# CC1312PSIP register map
File version: 1.0
CPU: CM4 1.0, other endian, MPU, FPU, 3 interrupt priority bits
Registers are 32-bit, read-write, reset 0x0 unless marked. A register's access mark holds for its fields unless they carry their own. Offsets are from the block's base; [hi:lo] are bit positions; {n}, {i} and the like mark numbered series; 'fields as' and 'values as' point back to an identical list.

## CPU_DWT — Cortex-M's Data watchpoint and Trace (DWT)
Base 0xE0001000
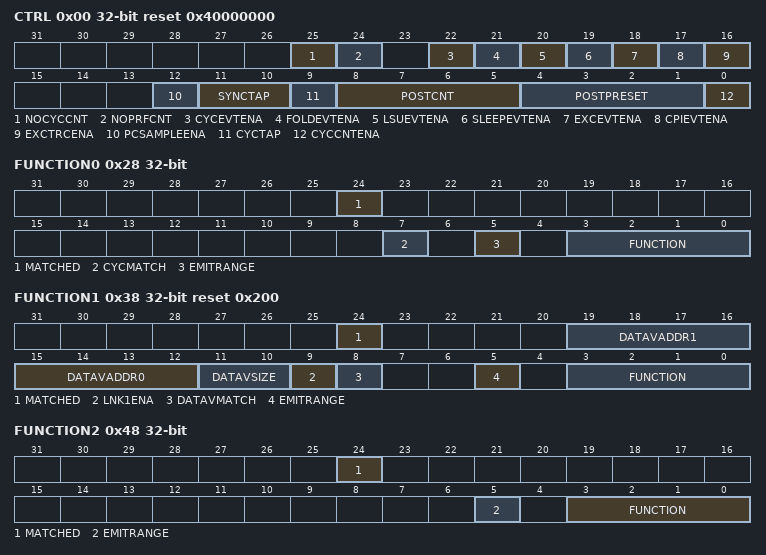
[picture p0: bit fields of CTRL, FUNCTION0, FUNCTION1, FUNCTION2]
0x00 CTRL reset 0x40000000 — Control Use the DWT Control Register to enable the DWT unit.
  [25] NOCYCCNT — [25:25] When set, CYCCNT is not supported.
  [24] NOPRFCNT — [24:24] When set, FOLDCNT, LSUCNT, SLEEPCNT, EXCCNT, and CPICNT are not supported.
  [22] CYCEVTENA — [22:22] Enables Cycle count event. Emits an event when the POSTCNT counter triggers it. See CYCTAP and POSTPRESET for details. This event is only emitted if PCSAMPLEENA is disabled. PCSAMPLEENA overrides the setting of this bit. 0: Cycle count events disabled 1: Cycle count events enabled
  [21] FOLDEVTENA — [21:21] Enables Folded instruction count event. Emits an event when FOLDCNT overflows (every 256 cycles of folded instructions). A folded instruction is one that does not incur even one cycle to execute. For example, an IT instruction is folded away and so does not use up one cycle. 0: Folded instruction count events disabled. 1: Folded instruction count events enabled.
  [20] LSUEVTENA — [20:20] Enables LSU count event. Emits an event when LSUCNT overflows (every 256 cycles of LSU operation). LSU counts include all LSU costs after the initial cycle for the instruction. 0: LSU count events disabled. 1: LSU count events enabled.
  [19] SLEEPEVTENA — [19:19] Enables Sleep count event. Emits an event when SLEEPCNT overflows (every 256 cycles that the processor is sleeping). 0: Sleep count events disabled. 1: Sleep count events enabled.
  [18] EXCEVTENA — [18:18] Enables Interrupt overhead event. Emits an event when EXCCNT overflows (every 256 cycles of interrupt overhead). 0x0: Interrupt overhead event disabled. 0x1: Interrupt overhead event enabled.
  [17] CPIEVTENA — [17:17] Enables CPI count event. Emits an event when CPICNT overflows (every 256 cycles of multi-cycle instructions). 0: CPI counter events disabled. 1: CPI counter events enabled.
  [16] EXCTRCENA — [16:16] Enables Interrupt event tracing. 0: Interrupt event trace disabled. 1: Interrupt event trace enabled.
  [12] PCSAMPLEENA — [12:12] Enables PC Sampling event. A PC sample event is emitted when the POSTCNT counter triggers it. See CYCTAP and POSTPRESET for details. Enabling this bit overrides CYCEVTENA. 0: PC Sampling event disabled. 1: Sampling event enabled.
  [11:10] SYNCTAP — [11:10] Selects a synchronization packet rate. CYCCNTENA and CPU_ITM:TCR.SYNCENA must also be enabled for this feature. Synchronization packets (if enabled) are generated on tap transitions (0 to1 or 1 to 0).
    3=BIT28 (Tap at bit 28 of CYCCNT); 2=BIT26 (Tap at bit 26 of CYCCNT); 1=BIT24 (Tap at bit 24 of CYCCNT); 0=DIS (Disabled. No synchronization packets)
  [9] CYCTAP — [9:9] Selects a tap on CYCCNT. These are spaced at bits [6] and [10]. When the selected bit in CYCCNT changes from 0 to 1 or 1 to 0, it emits into the POSTCNT, post-scalar counter. That counter then counts down. On a bit change when post-scalar is 0, it triggers an event for PC sampling or cycle count event (see details in CYCEVTENA).
    1=BIT10 (Selects bit [10] to tap); 0=BIT6 (Selects bit [6] to tap)
  [8:5] POSTCNT — [8:5] Post-scalar counter for CYCTAP. When the selected tapped bit changes from 0 to 1 or 1 to 0, the post scalar counter is down-counted when not 0. If 0, it triggers an event for PCSAMPLEENA or CYCEVTENA use. It also reloads with the value from POSTPRESET.
  [4:1] POSTPRESET — [4:1] Reload value for post-scalar counter POSTCNT. When 0, events are triggered on each tap change (a power of 2). If this field has a non-0 value, it forms a count-down value, to be reloaded into POSTCNT each time it reaches 0. For example, a value 1 in this register means an event is formed every other tap change.
  [0] CYCCNTENA — [0:0] Enable CYCCNT, allowing it to increment and generate synchronization and count events. If NOCYCCNT = 1, this bit reads zero and ignore writes.
0x04 CYCCNT — Current PC Sampler Cycle Count This register is used to count the number of core cycles. This counter can measure elapsed execution time. This is a free-running counter (this counter will not advance in power modes where free-running clock to CPU stops). The counter has three functions: 1: When CTRL.PCSAMPLEENA = 1, the PC is sampled and emitted when the selected tapped bit changes value (0 to 1 or 1 to 0) and any post-scalar value counts to 0. 2: When CTRL.CYCEVTENA = 1 , (and CTRL.PCSAMPLEENA = 0), an event is emitted when the selected tapped bit changes value (0 to 1 or 1 to 0) and any post-scalar value counts to 0. 3: Applications and debuggers can use the counter to measure elapsed execution time. By subtracting a start and an end time, an application can measure time between in-core clocks (other than when Halted in debug). This is valid to 2^32 core clock cycles (for example, almost 89.5 seconds at 48MHz).
  [31:0] CYCCNT — [31:0] Current PC Sampler Cycle Counter count value. When enabled, this counter counts the number of core cycles, except when the core is halted. The cycle counter is a free running counter, counting upwards (this counter will not advance in power modes where free-running clock to CPU stops). It wraps around to 0 on overflow. The debugger must initialize this to 0 when first enabling.
0x08 CPICNT — CPI Count This register is used to count the total number of instruction cycles beyond the first cycle.
  [7:0] CPICNT — [7:0] Current CPI counter value. Increments on the additional cycles (the first cycle is not counted) required to execute all instructions except those recorded by LSUCNT. This counter also increments on all instruction fetch stalls. If CTRL.CPIEVTENA is set, an event is emitted when the counter overflows. This counter initializes to 0 when it is enabled using CTRL.CPIEVTENA.
0x0C EXCCNT — Exception Overhead Count This register is used to count the total cycles spent in interrupt processing.
  [7:0] EXCCNT — [7:0] Current interrupt overhead counter value. Counts the total cycles spent in interrupt processing (for example entry stacking, return unstacking, pre-emption). An event is emitted on counter overflow (every 256 cycles). This counter initializes to 0 when it is enabled using CTRL.EXCEVTENA.
0x10 SLEEPCNT — Sleep Count This register is used to count the total number of cycles during which the processor is sleeping.
  [7:0] SLEEPCNT — [7:0] Sleep counter. Counts the number of cycles during which the processor is sleeping. An event is emitted on counter overflow (every 256 cycles). This counter initializes to 0 when it is enabled using CTRL.SLEEPEVTENA. Note that the sleep counter is clocked using CPU's free-running clock. In some power modes the free-running clock to CPU is gated to minimize power consumption. This means that the sleep counter will be invalid in these power modes.
0x14 LSUCNT — LSU Count This register is used to count the total number of cycles during which the processor is processing an LSU operation beyond the first cycle.
  [7:0] LSUCNT — [7:0] LSU counter. This counts the total number of cycles that the processor is processing an LSU operation. The initial execution cost of the instruction is not counted. For example, an LDR that takes two cycles to complete increments this counter one cycle. Equivalently, an LDR that stalls for two cycles (i.e. takes four cycles to execute), increments this counter three times. An event is emitted on counter overflow (every 256 cycles). This counter initializes to 0 when it is enabled using CTRL.LSUEVTENA.
0x18 FOLDCNT — Fold Count This register is used to count the total number of folded instructions. The counter increments on each instruction which takes 0 cycles.
  [7:0] FOLDCNT — [7:0] This counts the total number folded instructions. This counter initializes to 0 when it is enabled using CTRL.FOLDEVTENA.
0x1C PCSR — Program Counter Sample This register is used to enable coarse-grained software profiling using a debug agent, without changing the currently executing code. If the core is not in debug state, the value returned is the instruction address of a recently executed instruction. If the core is in debug state, the value returned is 0xFFFFFFFF.
  [31:0] EIASAMPLE ro — [31:0] Execution instruction address sample, or 0xFFFFFFFF if the core is halted.
0x20 COMP0 — Comparator 0 This register is used to write the reference value for comparator 0.
  [31:0] COMP — [31:0] Reference value to compare against PC or the data address as given by FUNCTION0. Comparator 0 can also compare against the value of the PC Sampler Counter (CYCCNT).
{0x24+0x10*i} MASK{i} (i=0..3) — Mask {i} Use the DWT Mask Registers {i} to apply a mask to data addresses when matching against COMP{i}.
  [3:0] MASK — [3:0] Mask on data address when matching against COMP{i}. This is the size of the ignore mask. That is, DWT matching is performed as:(ADDR ANDed with (0xFFFF left bit-shifted by MASK)) == COMP{i}. However, the actual comparison is slightly more complex to enable matching an address wherever it appears on a bus. So, if COMP{i} is 3, this matches a word access of 0, because 3 would be within the word.
0x28 FUNCTION0 — Function 0 Use the DWT Function Registers 0 to control the operation of the comparator 0. This comparator can: 1. Match against either the PC or the data address. This is controlled by CYCMATCH. This function is only available for comparator 0 (COMP0). 2. Emit data or PC couples, trigger the ETM, or generate a watchpoint depending on the operation defined by FUNCTION.
  [24] MATCHED — [24:24] This bit is set when the comparator matches, and indicates that the operation defined by FUNCTION has occurred since this bit was last read. This bit is cleared on read.
  [7] CYCMATCH — [7:7] This bit is only available in comparator 0. When set, COMP0 will compare against the cycle counter (CYCCNT).
  [5] EMITRANGE — [5:5] Emit range field. This bit permits emitting offset when range match occurs. PC sampling is not supported when emit range is enabled. This field only applies for: FUNCTION = 1, 2, 3, 12, 13, 14, and 15.
  [3:0] FUNCTION — [3:0] Function settings. 0x0: Disabled 0x1: EMITRANGE = 0, sample and emit PC through ITM. EMITRANGE = 1, emit address offset through ITM 0x2: EMITRANGE = 0, emit data through ITM on read and write. EMITRANGE = 1, emit data and address offset through ITM on read or write. 0x3: EMITRANGE = 0, sample PC and data value through ITM on read or write. EMITRANGE = 1, emit address offset and data value through ITM on read or write. 0x4: Watchpoint on PC match. 0x5: Watchpoint on read. 0x6: Watchpoint on write. 0x7: Watchpoint on read or write. 0x8: ETM trigger on PC match 0x9: ETM trigger on read 0xA: ETM trigger on write 0xB: ETM trigger on read or write 0xC: EMITRANGE = 0, sample data for read transfers. EMITRANGE = 1, sample Daddr (lower 16 bits) for read transfers 0xD: EMITRANGE = 0, sample data for write transfers. EMITRANGE = 1, sample Daddr (lower 16 bits) for write transfers 0xE: EMITRANGE = 0, sample PC + data for read transfers. EMITRANGE = 1, sample Daddr (lower 16 bits) + data for read transfers 0xF: EMITRANGE = 0, sample PC + data for write transfers. EMITRANGE = 1, sample Daddr (lower 16 bits) + data for write transfers Note 1: If the ETM is not fitted, then ETM trigger is not possible. Note 2: Data value is only sampled for accesses that do not fault (MPU or bus fault). The PC is sampled irrespective of any faults. The PC is only sampled for the first address of a burst. Note 3: PC match is not recommended for watchpoints because it stops after the instruction. It mainly guards and triggers the ETM.
0x30 COMP1 — Comparator 1 This register is used to write the reference value for comparator 1.
  [31:0] COMP — [31:0] Reference value to compare against PC or the data address as given by FUNCTION1. Comparator 1 can also compare data values. So this register can contain reference values for data matching.
0x38 FUNCTION1 reset 0x200 — Function 1 Use the DWT Function Registers 1 to control the operation of the comparator 1. This comparator can: 1. Perform data value comparisons if associated address comparators have performed an address match. This function is only available for comparator 1 (COMP1). 2. Emit data or PC couples, trigger the ETM, or generate a watchpoint depending on the operation defined by FUNCTION.
  [24] MATCHED — [24:24] This bit is set when the comparator matches, and indicates that the operation defined by FUNCTION has occurred since this bit was last read. This bit is cleared on read.
  [19:16] DATAVADDR1 — [19:16] Identity of a second linked address comparator for data value matching when DATAVMATCH == 1 and LNK1ENA == 1.
  [15:12] DATAVADDR0 — [15:12] Identity of a linked address comparator for data value matching when DATAVMATCH == 1.
  [11:10] DATAVSIZE — [11:10] Defines the size of the data in the COMP1 register that is to be matched: 0x0: Byte 0x1: Halfword 0x2: Word 0x3: Unpredictable.
  [9] LNK1ENA ro — [9:9] Read only bit-field only supported in comparator 1. 0: DATAVADDR1 not supported 1: DATAVADDR1 supported (enabled)
  [8] DATAVMATCH — [8:8] Data match feature: 0: Perform address comparison 1: Perform data value compare. The comparators given by DATAVADDR0 and DATAVADDR1 provide the address for the data comparison. The FUNCTION setting for the comparators given by DATAVADDR0 and DATAVADDR1 are overridden and those comparators only provide the address match for the data comparison. This bit is only available in comparator 1.
  [5] EMITRANGE — [5:5] Emit range field. This bit permits emitting offset when range match occurs. PC sampling is not supported when emit range is enabled. This field only applies for: FUNCTION = 1, 2, 3, 12, 13, 14, and 15.
  [3:0] FUNCTION — [3:0] Function settings: 0x0: Disabled 0x1: EMITRANGE = 0, sample and emit PC through ITM. EMITRANGE = 1, emit address offset through ITM 0x2: EMITRANGE = 0, emit data through ITM on read and write. EMITRANGE = 1, emit data and address offset through ITM on read or write. 0x3: EMITRANGE = 0, sample PC and data value through ITM on read or write. EMITRANGE = 1, emit address offset and data value through ITM on read or write. 0x4: Watchpoint on PC match. 0x5: Watchpoint on read. 0x6: Watchpoint on write. 0x7: Watchpoint on read or write. 0x8: ETM trigger on PC match 0x9: ETM trigger on read 0xA: ETM trigger on write 0xB: ETM trigger on read or write 0xC: EMITRANGE = 0, sample data for read transfers. EMITRANGE = 1, sample Daddr (lower 16 bits) for read transfers 0xD: EMITRANGE = 0, sample data for write transfers. EMITRANGE = 1, sample Daddr (lower 16 bits) for write transfers 0xE: EMITRANGE = 0, sample PC + data for read transfers. EMITRANGE = 1, sample Daddr (lower 16 bits) + data for read transfers 0xF: EMITRANGE = 0, sample PC + data for write transfers. EMITRANGE = 1, sample Daddr (lower 16 bits) + data for write transfers Note 1: If the ETM is not fitted, then ETM trigger is not possible. Note 2: Data value is only sampled for accesses that do not fault (MPU or bus fault). The PC is sampled irrespective of any faults. The PC is only sampled for the first address of a burst. Note 3: FUNCTION is overridden for comparators given by DATAVADDR0 and DATAVADDR1 if DATAVMATCH is also set. The comparators given by DATAVADDR0 and DATAVADDR1 can then only perform address comparator matches for comparator 1 data matches. Note 4: If the data matching functionality is not included during implementation it is not possible to set DATAVADDR0, DATAVADDR1, or DATAVMATCH. This means that the data matching functionality is not available in the implementation. Test the availability of data matching by writing and reading DATAVMATCH. If it is not settable then data matching is unavailable. Note 5: PC match is not recommended for watchpoints because it stops after the instruction. It mainly guards and triggers the ETM.
0x40 COMP2 — Comparator 2 This register is used to write the reference value for comparator 2.
  [31:0] COMP — [31:0] Reference value to compare against PC or the data address as given by FUNCTION2.
0x48 FUNCTION2 — Function 2 Use the DWT Function Registers 2 to control the operation of the comparator 2. This comparator can emit data or PC couples, trigger the ETM, or generate a watchpoint depending on the operation defined by FUNCTION.
  [24] MATCHED — [24:24] This bit is set when the comparator matches, and indicates that the operation defined by FUNCTION has occurred since this bit was last read. This bit is cleared on read.
  [5] EMITRANGE — [5:5] Emit range field. This bit permits emitting offset when range match occurs. PC sampling is not supported when emit range is enabled. This field only applies for: FUNCTION = 1, 2, 3, 12, 13, 14, and 15.
  [3:0] FUNCTION — [3:0] Function settings. 0x0: Disabled 0x1: EMITRANGE = 0, sample and emit PC through ITM. EMITRANGE = 1, emit address offset through ITM 0x2: EMITRANGE = 0, emit data through ITM on read and write. EMITRANGE = 1, emit data and address offset through ITM on read or write. 0x3: EMITRANGE = 0, sample PC and data value through ITM on read or write. EMITRANGE = 1, emit address offset and data value through ITM on read or write. 0x4: Watchpoint on PC match. 0x5: Watchpoint on read. 0x6: Watchpoint on write. 0x7: Watchpoint on read or write. 0x8: ETM trigger on PC match 0x9: ETM trigger on read 0xA: ETM trigger on write 0xB: ETM trigger on read or write 0xC: EMITRANGE = 0, sample data for read transfers. EMITRANGE = 1, sample Daddr (lower 16 bits) for read transfers 0xD: EMITRANGE = 0, sample data for write transfers. EMITRANGE = 1, sample Daddr (lower 16 bits) for write transfers 0xE: EMITRANGE = 0, sample PC + data for read transfers. EMITRANGE = 1, sample Daddr (lower 16 bits) + data for read transfers 0xF: EMITRANGE = 0, sample PC + data for write transfers. EMITRANGE = 1, sample Daddr (lower 16 bits) + data for write transfers Note 1: If the ETM is not fitted, then ETM trigger is not possible. Note 2: Data value is only sampled for accesses that do not fault (MPU or bus fault). The PC is sampled irrespective of any faults. The PC is only sampled for the first address of a burst. Note 3: PC match is not recommended for watchpoints because it stops after the instruction. It mainly guards and triggers the ETM.
0x50 COMP3 — Comparator 3 This register is used to write the reference value for comparator 3.
  [31:0] COMP — [31:0] Reference value to compare against PC or the data address as given by FUNCTION3.
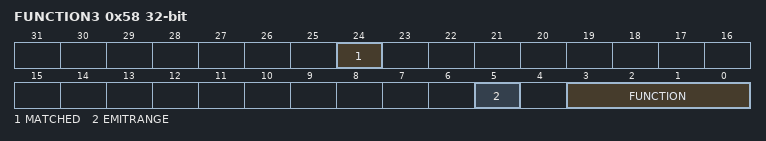
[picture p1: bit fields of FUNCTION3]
0x58 FUNCTION3 — Function 3 Use the DWT Function Registers 3 to control the operation of the comparator 3. This comparator can emit data or PC couples, trigger the ETM, or generate a watchpoint depending on the operation defined by FUNCTION.
  fields as FUNCTION2
